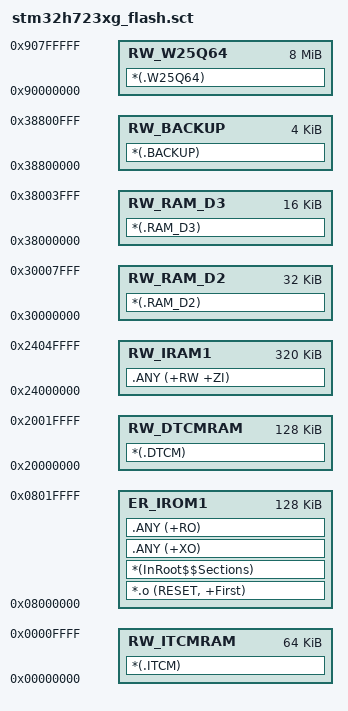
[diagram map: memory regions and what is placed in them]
; 加载区 起始地址 大小
LR_IROM1 0x08000000 0x00020000  {
  ; 加载地址 = 执行地址
  ER_IROM1 0x08000000 0x00020000  {
    *.o (RESET, +First)
    *(InRoot$$Sections)
    .ANY (+XO)
    .ANY (+RO)
  }
  ; 内部RAM区 起始地址 大小
  RW_IRAM1 0x24000000 0x00050000  {
    .ANY (+RW +ZI)
  }

  ; DTCM RAM区 起始地址 大小
  RW_DTCMRAM 0x20000000 0x00020000  {
    *(.DTCM)
  }

  ; RAM_D2区 起始地址 大小
  RW_RAM_D2 0x30000000 0x00008000  {
    *(.RAM_D2)
  }

  ; RAM_D3区 起始地址 大小
  RW_RAM_D3 0x38000000 0x00004000  {
    *(.RAM_D3)
  }

  ; ITCM RAM区 起始地址 大小
  RW_ITCMRAM 0x00000000 0x00010000  {
    *(.ITCM)
  }

  ; BACKUP ARM区 起始地址 大小
  RW_BACKUP 0x38800000 0x00001000  {
    *(.BACKUP)
  }

  ; 外部W25Q64 Flash区 起始地址 大小
  RW_W25Q64 0x90000000 0x00800000  {
    *(.W25Q64)
  }

}
